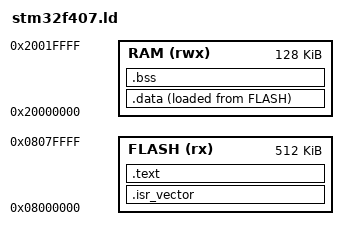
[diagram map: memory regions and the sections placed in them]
/*
 * Linker script for STM32F407
 *   FLASH: 512 KB @ 0x08000000
 *   RAM:   128 KB @ 0x20000000
 */

ENTRY(Reset_Handler)

_estack = 0x20000000 + 128K;   /* top of RAM (stack grows down) */

MEMORY
{
    FLASH (rx)  : ORIGIN = 0x08000000, LENGTH = 512K
    RAM   (rwx) : ORIGIN = 0x20000000, LENGTH = 128K
}

SECTIONS
{
    .isr_vector :
    {
        . = ALIGN(4);
        KEEP(*(.isr_vector))
        . = ALIGN(4);
    } > FLASH

    .text :
    {
        . = ALIGN(4);
        *(.text)
        *(.text*)
        *(.rodata)
        *(.rodata*)
        . = ALIGN(4);
        _etext = .;
    } > FLASH

    _sidata = LOADADDR(.data);

    .data :
    {
        . = ALIGN(4);
        _sdata = .;
        *(.data)
        *(.data*)
        . = ALIGN(4);
        _edata = .;
    } > RAM AT > FLASH

    .bss :
    {
        . = ALIGN(4);
        _sbss = .;
        *(.bss)
        *(.bss*)
        *(COMMON)
        . = ALIGN(4);
        _ebss = .;
    } > RAM

    /DISCARD/ :
    {
        *(.ARM.exidx*)
        *(.ARM.extab*)
    }
}
